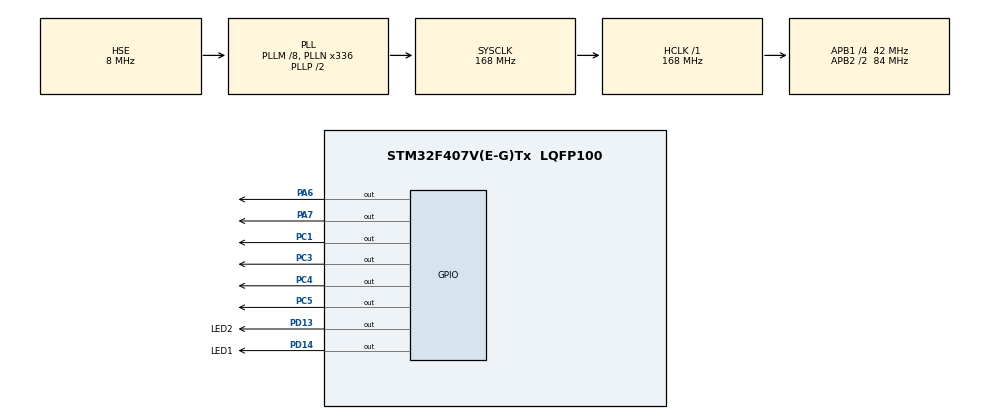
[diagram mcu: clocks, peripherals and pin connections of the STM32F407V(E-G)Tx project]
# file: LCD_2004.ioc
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Mcu.Family=STM32F4
Mcu.Name=STM32F407V(E-G)Tx
Mcu.Package=LQFP100
NVIC.PriorityGroup=NVIC_PRIORITYGROUP_0
NVIC.TIM3_IRQn=true\:0\:0\:false\:false\:true\:true\:true\:true
PA6.Signal=GPIO_Output
PA7.Signal=GPIO_Output
PC1.Signal=GPIO_Output
PC14-OSC32_IN.Mode=LSE-External-Oscillator
PC14-OSC32_IN.Signal=RCC_OSC32_IN
PC15-OSC32_OUT.Mode=LSE-External-Oscillator
PC15-OSC32_OUT.Signal=RCC_OSC32_OUT
PC3.Signal=GPIO_Output
PC4.Signal=GPIO_Output
PC5.Signal=GPIO_Output
PD13.GPIO_Label=LED2
PD13.Signal=GPIO_Output
PD14.GPIO_Label=LED1
PD14.Signal=GPIO_Output
PH0-OSC_IN.Mode=HSE-External-Clock-Source
PH0-OSC_IN.Signal=RCC_OSC_IN
PH1-OSC_OUT.Mode=HSE-External-Clock-Source
PH1-OSC_OUT.Signal=RCC_OSC_OUT
ProjectManager.HeapSize=0x200
ProjectManager.StackSize=0x400
ProjectManager.TargetToolchain=STM32CubeIDE
RCC.48MHZClocksFreq_Value=48000000
RCC.AHBFreq_Value=168000000
RCC.APB1CLKDivider=RCC_HCLK_DIV4
RCC.APB1Freq_Value=42000000
RCC.APB1TimFreq_Value=84000000
RCC.APB2CLKDivider=RCC_HCLK_DIV2
RCC.APB2Freq_Value=84000000
RCC.APB2TimFreq_Value=168000000
RCC.CortexFreq_Value=168000000
RCC.HCLKFreq_Value=168000000
RCC.HSE_VALUE=8000000
RCC.HSI_VALUE=16000000
RCC.PLLM=8
RCC.PLLN=336
RCC.PLLQ=7
RCC.PLLSourceVirtual=RCC_PLLSOURCE_HSE
RCC.SYSCLKFreq_VALUE=168000000
RCC.SYSCLKSource=RCC_SYSCLKSOURCE_PLLCLK
RCC.VCOOutputFreq_Value=336000000
TIM3.Period=10000-1
TIM3.Prescaler=16800-1
VP_TIM3_VS_ClockSourceINT.Mode=Internal
board=STM32F407G-DISC1

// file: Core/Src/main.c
/* USER CODE BEGIN Header */
/**
  ******************************************************************************
  * @file           : main.c
  * @brief          : Main program body
  ******************************************************************************
  * @attention
  *
  * Copyright (c) 2024 STMicroelectronics.
  * All rights reserved.
  *
  * This software is licensed under terms that can be found in the LICENSE file
  * in the root directory of this software component.
  * If no LICENSE file comes with this software, it is provided AS-IS.
  *
  ******************************************************************************
  */
/* USER CODE END Header */
#include "main.h"

TIM_HandleTypeDef htim3;

void SystemClock_Config(void);
static void MX_GPIO_Init(void);
static void MX_TIM3_Init(void);

int main(void)
{

  /* MCU Configuration--------------------------------------------------------*/

  /* Reset of all peripherals, Initializes the Flash interface and the Systick. */
  HAL_Init();

  /* Configure the system clock */
  SystemClock_Config();

  /* Initialize all configured peripherals */
  MX_GPIO_Init();
  MX_TIM3_Init();
  /* USER CODE BEGIN 2 */

  HAL_TIM_Base_Start_IT(&htim3);
  // Lcd_PortType ports[] = { D4_GPIO_Port, D5_GPIO_Port, D6_GPIO_Port, D7_GPIO_Port };
    Lcd_PortType ports[] = { GPIOC, GPIOC, GPIOA, GPIOA };
    // Lcd_PinType pins[] = {D4_Pin, D5_Pin, D6_Pin, D7_Pin};
    Lcd_PinType pins[] = {GPIO_PIN_4, GPIO_PIN_5, GPIO_PIN_6, GPIO_PIN_7};
    Lcd_HandleTypeDef lcd;
    // Lcd_create(ports, pins, RS_GPIO_Port, RS_Pin, EN_GPIO_Port, EN_Pin, LCD_4_BIT_MODE);
    lcd = Lcd_create(ports, pins, GPIOC, GPIO_PIN_3, GPIOC, GPIO_PIN_1, LCD_4_BIT_MODE);
    Lcd_cursor(&lcd, 0,1);
    Lcd_string(&lcd, "CMTEQ");

    Lcd_cursor(&lcd, 3,0);
    Lcd_string(&lcd, "Chad");
      for ( int x = 1; x <= 200 ; x++ )
      {
        Lcd_cursor(&lcd, 1,7);
        Lcd_int(&lcd, x);
        HAL_Delay (1000);
      }
  /* USER CODE END 2 */

  /* Infinite loop */
  while (1)
  {

  }
}

void HAL_TIM_PeriodElapsedCallback(TIM_HandleTypeDef *htim)
{
  /* Prevent unused argument(s) compilation warning */
  UNUSED(htim);
  HAL_GPIO_TogglePin(GPIOD, LED2_Pin);
}

void SystemClock_Config(void)
{
  RCC_OscInitTypeDef RCC_OscInitStruct = {0};
  RCC_ClkInitTypeDef RCC_ClkInitStruct = {0};

  /** Configure the main internal regulator output voltage
  */
  __HAL_RCC_PWR_CLK_ENABLE();
  __HAL_PWR_VOLTAGESCALING_CONFIG(PWR_REGULATOR_VOLTAGE_SCALE1);

  /** Initializes the RCC Oscillators according to the specified parameters
  * in the RCC_OscInitTypeDef structure.
  */
  RCC_OscInitStruct.OscillatorType = RCC_OSCILLATORTYPE_HSE;
  RCC_OscInitStruct.HSEState = RCC_HSE_BYPASS;
  RCC_OscInitStruct.PLL.PLLState = RCC_PLL_ON;
  RCC_OscInitStruct.PLL.PLLSource = RCC_PLLSOURCE_HSE;
  RCC_OscInitStruct.PLL.PLLM = 8;
  RCC_OscInitStruct.PLL.PLLN = 336;
  RCC_OscInitStruct.PLL.PLLP = RCC_PLLP_DIV2;
  RCC_OscInitStruct.PLL.PLLQ = 7;
  if (HAL_RCC_OscConfig(&RCC_OscInitStruct) != HAL_OK)
  {
    Error_Handler();
  }

  /** Initializes the CPU, AHB and APB buses clocks
  */
  RCC_ClkInitStruct.ClockType = RCC_CLOCKTYPE_HCLK|RCC_CLOCKTYPE_SYSCLK
                              |RCC_CLOCKTYPE_PCLK1|RCC_CLOCKTYPE_PCLK2;
  RCC_ClkInitStruct.SYSCLKSource = RCC_SYSCLKSOURCE_PLLCLK;
  RCC_ClkInitStruct.AHBCLKDivider = RCC_SYSCLK_DIV1;
  RCC_ClkInitStruct.APB1CLKDivider = RCC_HCLK_DIV4;
  RCC_ClkInitStruct.APB2CLKDivider = RCC_HCLK_DIV2;

  if (HAL_RCC_ClockConfig(&RCC_ClkInitStruct, FLASH_LATENCY_5) != HAL_OK)
  {
    Error_Handler();
  }
}

static void MX_TIM3_Init(void)
{

  TIM_ClockConfigTypeDef sClockSourceConfig = {0};
  TIM_MasterConfigTypeDef sMasterConfig = {0};

  htim3.Instance = TIM3;
  htim3.Init.Prescaler = 16800-1;
  htim3.Init.CounterMode = TIM_COUNTERMODE_UP;
  htim3.Init.Period = 10000-1;
  htim3.Init.ClockDivision = TIM_CLOCKDIVISION_DIV1;
  htim3.Init.AutoReloadPreload = TIM_AUTORELOAD_PRELOAD_DISABLE;
  if (HAL_TIM_Base_Init(&htim3) != HAL_OK)
  {
    Error_Handler();
  }
  sClockSourceConfig.ClockSource = TIM_CLOCKSOURCE_INTERNAL;
  if (HAL_TIM_ConfigClockSource(&htim3, &sClockSourceConfig) != HAL_OK)
  {
    Error_Handler();
  }
  sMasterConfig.MasterOutputTrigger = TIM_TRGO_RESET;
  sMasterConfig.MasterSlaveMode = TIM_MASTERSLAVEMODE_DISABLE;
  if (HAL_TIMEx_MasterConfigSynchronization(&htim3, &sMasterConfig) != HAL_OK)
  {
    Error_Handler();
  }

}

static void MX_GPIO_Init(void)
{
  GPIO_InitTypeDef GPIO_InitStruct = {0};

  /* GPIO Ports Clock Enable */
  __HAL_RCC_GPIOC_CLK_ENABLE();
  __HAL_RCC_GPIOH_CLK_ENABLE();
  __HAL_RCC_GPIOA_CLK_ENABLE();
  __HAL_RCC_GPIOD_CLK_ENABLE();

  /*Configure GPIO pin Output Level */
  HAL_GPIO_WritePin(GPIOC, GPIO_PIN_1|GPIO_PIN_3|GPIO_PIN_4|GPIO_PIN_5, GPIO_PIN_RESET);

  /*Configure GPIO pin Output Level */
  HAL_GPIO_WritePin(GPIOA, GPIO_PIN_6|GPIO_PIN_7, GPIO_PIN_RESET);

  /*Configure GPIO pin Output Level */
  HAL_GPIO_WritePin(GPIOD, LED2_Pin|LED1_Pin, GPIO_PIN_RESET);

  /*Configure GPIO pins : PC1 PC3 PC4 PC5 */
  GPIO_InitStruct.Pin = GPIO_PIN_1|GPIO_PIN_3|GPIO_PIN_4|GPIO_PIN_5;
  GPIO_InitStruct.Mode = GPIO_MODE_OUTPUT_PP;
  GPIO_InitStruct.Pull = GPIO_NOPULL;
  GPIO_InitStruct.Speed = GPIO_SPEED_FREQ_LOW;
  HAL_GPIO_Init(GPIOC, &GPIO_InitStruct);

  /*Configure GPIO pins : PA6 PA7 */
  GPIO_InitStruct.Pin = GPIO_PIN_6|GPIO_PIN_7;
  GPIO_InitStruct.Mode = GPIO_MODE_OUTPUT_PP;
  GPIO_InitStruct.Pull = GPIO_NOPULL;
  GPIO_InitStruct.Speed = GPIO_SPEED_FREQ_LOW;
  HAL_GPIO_Init(GPIOA, &GPIO_InitStruct);

  /*Configure GPIO pins : LED2_Pin LED1_Pin */
  GPIO_InitStruct.Pin = LED2_Pin|LED1_Pin;
  GPIO_InitStruct.Mode = GPIO_MODE_OUTPUT_PP;
  GPIO_InitStruct.Pull = GPIO_NOPULL;
  GPIO_InitStruct.Speed = GPIO_SPEED_FREQ_LOW;
  HAL_GPIO_Init(GPIOD, &GPIO_InitStruct);

}

void Error_Handler(void)
{
  __disable_irq();
  while (1)
  {
  }
}
